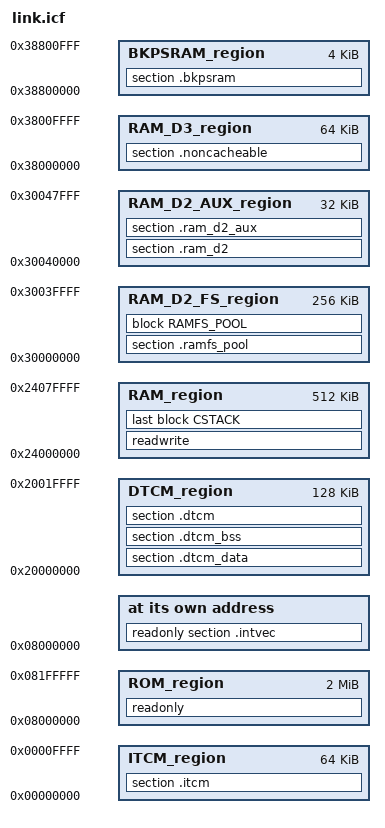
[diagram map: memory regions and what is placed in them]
/*###ICF### Section handled by ICF editor, don't touch! ****/
/* STM32H743IIT6 memory map */
/*-Specials-*/
define symbol __ICFEDIT_intvec_start__ = 0x08000000;
/*-Memory Regions-*/
define symbol __ICFEDIT_region_ROM_start__       = 0x08000000;
define symbol __ICFEDIT_region_ROM_end__         = 0x081FFFFF;
define symbol __ICFEDIT_region_ITCM_start__      = 0x00000000;
define symbol __ICFEDIT_region_ITCM_end__        = 0x0000FFFF;
define symbol __ICFEDIT_region_DTCM_start__      = 0x20000000;
define symbol __ICFEDIT_region_DTCM_end__        = 0x2001FFFF;
define symbol __ICFEDIT_region_RAM_start__       = 0x24000000;
define symbol __ICFEDIT_region_RAM_end__         = 0x2407FFFF;
define symbol __ICFEDIT_region_RAM_D2_FS_start__ = 0x30000000;
define symbol __ICFEDIT_region_RAM_D2_FS_end__   = 0x3003FFFF;  /* 256KB ramfs */
define symbol __ICFEDIT_region_RAM_D2_AUX_start__= 0x30040000;
define symbol __ICFEDIT_region_RAM_D2_AUX_end__  = 0x30047FFF;  /* 32KB SRAM3 */
define symbol __ICFEDIT_region_RAM_D3_start__    = 0x38000000;
define symbol __ICFEDIT_region_RAM_D3_end__      = 0x3800FFFF;  /* 64KB USB/DMA */
define symbol __ICFEDIT_region_BKPSRAM_start__   = 0x38800000;
define symbol __ICFEDIT_region_BKPSRAM_end__     = 0x38800FFF;
/*-Sizes-*/
define symbol __ICFEDIT_size_cstack__ = 0x800;
define symbol __ICFEDIT_size_heap__   = 0x000;
/**** End of ICF editor section. ###ICF###*/

define memory mem with size = 4G;
define region ROM_region        = mem:[from __ICFEDIT_region_ROM_start__        to __ICFEDIT_region_ROM_end__];
define region ITCM_region       = mem:[from __ICFEDIT_region_ITCM_start__       to __ICFEDIT_region_ITCM_end__];
define region DTCM_region       = mem:[from __ICFEDIT_region_DTCM_start__       to __ICFEDIT_region_DTCM_end__];
define region RAM_region        = mem:[from __ICFEDIT_region_RAM_start__        to __ICFEDIT_region_RAM_end__];
define region RAM_D2_FS_region  = mem:[from __ICFEDIT_region_RAM_D2_FS_start__  to __ICFEDIT_region_RAM_D2_FS_end__];
define region RAM_D2_AUX_region = mem:[from __ICFEDIT_region_RAM_D2_AUX_start__ to __ICFEDIT_region_RAM_D2_AUX_end__];
define region RAM_D3_region     = mem:[from __ICFEDIT_region_RAM_D3_start__     to __ICFEDIT_region_RAM_D3_end__];
define region BKPSRAM_region    = mem:[from __ICFEDIT_region_BKPSRAM_start__    to __ICFEDIT_region_BKPSRAM_end__];

define block CSTACK with alignment = 8, size = __ICFEDIT_size_cstack__ { };
define block RAMFS_POOL with alignment = 4, size = 0x40000 { }; /* 256KB */

initialize by copy { readwrite };
do not initialize  { section .noinit, section .noncacheable, section .dtcm_bss,
                     section .ramfs_pool, section .ram_d2, section .ram_d2_aux,
                     section .bkpsram };

place at address mem:__ICFEDIT_intvec_start__ { readonly section .intvec };

place in ROM_region        { readonly };
place in ITCM_region       { section .itcm };
place in DTCM_region       { section .dtcm_data, section .dtcm_bss, section .dtcm };
place in RAM_region        { readwrite, last block CSTACK };
place in RAM_D2_FS_region  { section .ramfs_pool, block RAMFS_POOL };
place in RAM_D2_AUX_region { section .ram_d2, section .ram_d2_aux };
place in RAM_D3_region     { section .noncacheable };
place in BKPSRAM_region    { section .bkpsram };
